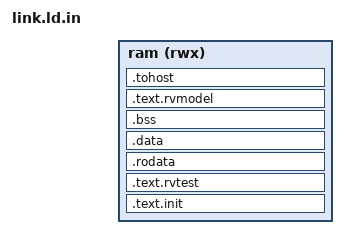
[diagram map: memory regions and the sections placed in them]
/* Places ACT reference and DUT sections identically in the selected platform RAM. */
/* Layout follows the pinned ACT4 config/cores/cvw/cvw-rv64gc/link.ld. */
/* SPDX-License-Identifier: Apache-2.0 */
OUTPUT_ARCH("riscv")
ENTRY(rvtest_entry_point)
MEMORY { ram (rwx) : ORIGIN = @RAM_ORIGIN@, LENGTH = @RAM_BYTES@ }
PROVIDE(__stack_size = 0x20000);
PROVIDE(__num_harts = 1);
SECTIONS
{
  .text.init @TEST_BASE@ : { *(.text.init) } > ram
  .text.rvtest . : { *(.text.rvtest) *(.text.rvtest.*) } > ram
  . = ALIGN(0x4000);
  .rodata . : { *(.rodata) *(.rodata.*) *(.srodata) *(.srodata.*) } > ram
  .data . : { *(.data) *(.data.*) *(.sdata) *(.sdata.*) } > ram
  . = ALIGN(16);
  .bss . : {
    __bss_start = .;
    *(.sbss) *(.sbss.*) *(.bss) *(.bss.*) *(COMMON)
    . = ALIGN(16);
    __bss_end = .;
  } > ram
  . = ALIGN(16);
  __stack_bottom = .;
  . += __stack_size * __num_harts;
  __stack_top = .;
  . = ALIGN(0x1000);
  .text.rvmodel . : { *(.text.rvmodel) *(.text.rvmodel.*) *(.text) *(.text.*) } > ram
  .tohost . : { *(.tohost) } > ram
  . = ALIGN(0x1000);
  _end = .;
  ASSERT(_end <= ORIGIN(ram) + LENGTH(ram), "ACT ELF exceeds platform RAM")
}
